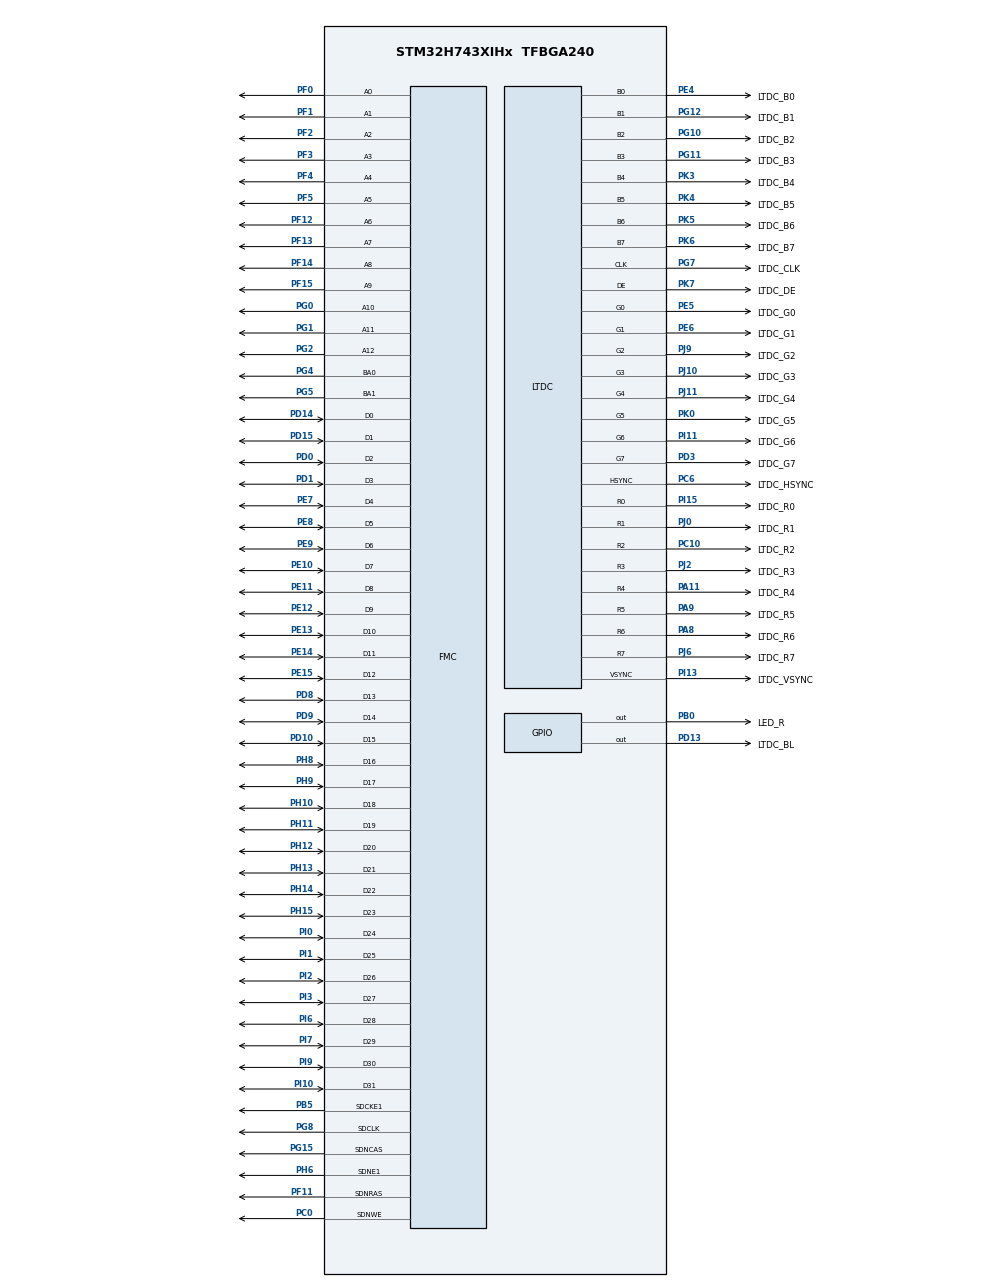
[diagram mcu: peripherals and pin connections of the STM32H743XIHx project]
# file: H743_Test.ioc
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CORTEX_M7.CPU_DCache=Enabled
CORTEX_M7.CPU_ICache=Enabled
DMA2D.Mode=DMA2D_R2M
FMC.BankMapConfig=FMC_SWAPBMAP_DISABLE
FMC.CASLatency1=FMC_SDRAM_CAS_LATENCY_3
FMC.ColumnBitsNumber1=FMC_SDRAM_COLUMN_BITS_NUM_9
FMC.ExitSelfRefreshDelay1=8
FMC.LoadToActiveDelay1=2
FMC.RCDDelay1=2
FMC.RPDelay1=2
FMC.ReadBurst1=FMC_SDRAM_RBURST_ENABLE
FMC.ReadPipeDelay1=FMC_SDRAM_RPIPE_DELAY_1
FMC.RowCycleDelay1=8
FMC.SDClockPeriod1=FMC_SDRAM_CLOCK_PERIOD_2
FMC.SelfRefreshTime1=5
FMC.WriteRecoveryTime1=4
LTDC.ActiveW=800
LTDC.Alpha0_L0=0
LTDC.Alpha_L0=255
LTDC.Alpha_L1=255
LTDC.BlendingFactor1_L0=LTDC_BLENDING_FACTOR1_PAxCA
LTDC.BlendingFactor1_L1=LTDC_BLENDING_FACTOR1_PAxCA
LTDC.BlendingFactor2_L0=LTDC_BLENDING_FACTOR2_PAxCA
LTDC.BlendingFactor2_L1=LTDC_BLENDING_FACTOR2_PAxCA
LTDC.FBStartAdress_L0=0xd2000000
LTDC.FBStartAdress_L1=0xD2000000+800*480*4
LTDC.HBP=46
LTDC.HFP=10
LTDC.HSync=1
LTDC.ImageHeight_L0=480
LTDC.ImageHeight_L1=480
LTDC.ImageWidth_L0=800
LTDC.ImageWidth_L1=800
LTDC.VBP=23
LTDC.VFP=22
LTDC.VSync=1
LTDC.WindowX1_L0=800
LTDC.WindowX1_L1=800
LTDC.WindowY1_L0=480
LTDC.WindowY1_L1=480
Mcu.Family=STM32H7
Mcu.Name=STM32H743XIHx
Mcu.Package=TFBGA240
NVIC.PriorityGroup=NVIC_PRIORITYGROUP_4
PA11.GPIO_Label=LTDC_R4
PA11.GPIO_PuPd=GPIO_PULLUP
PA11.GPIO_Speed=GPIO_SPEED_FREQ_VERY_HIGH
PA11.Mode=RGB888
PA11.Signal=LTDC_R4
PA8.GPIO_Label=LTDC_R6
PA8.GPIO_PuPd=GPIO_PULLUP
PA8.GPIO_Speed=GPIO_SPEED_FREQ_VERY_HIGH
PA8.Mode=RGB888
PA8.Signal=LTDC_R6
PA9.GPIO_Label=LTDC_R5
PA9.GPIO_PuPd=GPIO_PULLUP
PA9.GPIO_Speed=GPIO_SPEED_FREQ_VERY_HIGH
PA9.Mode=RGB888
PA9.Signal=LTDC_R5
PB0.GPIO_Label=LED_R
PB0.GPIO_PuPd=GPIO_PULLUP
PB0.GPIO_Speed=GPIO_SPEED_FREQ_HIGH
PB0.PinState=GPIO_PIN_SET
PB0.Signal=GPIO_Output
PB5.GPIO_Mode=GPIO_MODE_AF_PP
PB5.GPIO_PuPd=GPIO_PULLUP
PB5.GPIO_Speed_High_Default=GPIO_SPEED_FREQ_VERY_HIGH
PB5.Mode=SdramChipSelect2_1
PB5.Signal=FMC_SDCKE1
PC0.GPIO_Mode=GPIO_MODE_AF_PP
PC0.GPIO_PuPd=GPIO_PULLUP
PC0.GPIO_Speed_High_Default=GPIO_SPEED_FREQ_VERY_HIGH
PC0.Signal=FMC_SDNWE
PC10.GPIO_Label=LTDC_R2
PC10.GPIO_PuPd=GPIO_PULLUP
PC10.GPIO_Speed=GPIO_SPEED_FREQ_VERY_HIGH
PC10.Mode=RGB888
PC10.Signal=LTDC_R2
PC6.GPIO_Label=LTDC_HSYNC
PC6.GPIO_PuPd=GPIO_PULLUP
PC6.GPIO_Speed=GPIO_SPEED_FREQ_VERY_HIGH
PC6.Mode=RGB888
PC6.Signal=LTDC_HSYNC
PD0.GPIO_Mode=GPIO_MODE_AF_PP
PD0.GPIO_PuPd=GPIO_PULLUP
PD0.GPIO_Speed_High_Default=GPIO_SPEED_FREQ_VERY_HIGH
PD0.Signal=FMC_D2_DA2
PD1.GPIO_Mode=GPIO_MODE_AF_PP
PD1.GPIO_PuPd=GPIO_PULLUP
PD1.GPIO_Speed_High_Default=GPIO_SPEED_FREQ_VERY_HIGH
PD1.Signal=FMC_D3_DA3
PD10.GPIO_Mode=GPIO_MODE_AF_PP
PD10.GPIO_PuPd=GPIO_PULLUP
PD10.GPIO_Speed_High_Default=GPIO_SPEED_FREQ_VERY_HIGH
PD10.Signal=FMC_D15_DA15
PD13.GPIO_Label=LTDC_BL
PD13.GPIO_ModeDefaultOutputPP=GPIO_MODE_OUTPUT_PP
PD13.GPIO_PuPd=GPIO_PULLUP
PD13.GPIO_Speed=GPIO_SPEED_FREQ_HIGH
PD13.PinState=GPIO_PIN_SET
PD13.Signal=GPIO_Output
PD14.GPIO_Mode=GPIO_MODE_AF_PP
PD14.GPIO_PuPd=GPIO_PULLUP
PD14.GPIO_Speed_High_Default=GPIO_SPEED_FREQ_VERY_HIGH
PD14.Signal=FMC_D0_DA0
PD15.GPIO_Mode=GPIO_MODE_AF_PP
PD15.GPIO_PuPd=GPIO_PULLUP
PD15.GPIO_Speed_High_Default=GPIO_SPEED_FREQ_VERY_HIGH
PD15.Signal=FMC_D1_DA1
PD3.GPIO_Label=LTDC_G7
PD3.GPIO_PuPd=GPIO_PULLUP
PD3.GPIO_Speed=GPIO_SPEED_FREQ_VERY_HIGH
PD3.Mode=RGB888
PD3.Signal=LTDC_G7
PD8.GPIO_Mode=GPIO_MODE_AF_PP
PD8.GPIO_PuPd=GPIO_PULLUP
PD8.GPIO_Speed_High_Default=GPIO_SPEED_FREQ_VERY_HIGH
PD8.Signal=FMC_D13_DA13
PD9.GPIO_Mode=GPIO_MODE_AF_PP
PD9.GPIO_PuPd=GPIO_PULLUP
PD9.GPIO_Speed_High_Default=GPIO_SPEED_FREQ_VERY_HIGH
PD9.Signal=FMC_D14_DA14
PE10.GPIO_Mode=GPIO_MODE_AF_PP
PE10.GPIO_PuPd=GPIO_PULLUP
PE10.GPIO_Speed_High_Default=GPIO_SPEED_FREQ_VERY_HIGH
PE10.Signal=FMC_D7_DA7
PE11.GPIO_Mode=GPIO_MODE_AF_PP
PE11.GPIO_PuPd=GPIO_PULLUP
PE11.GPIO_Speed_High_Default=GPIO_SPEED_FREQ_VERY_HIGH
PE11.Signal=FMC_D8_DA8
PE12.GPIO_Mode=GPIO_MODE_AF_PP
PE12.GPIO_PuPd=GPIO_PULLUP
PE12.GPIO_Speed_High_Default=GPIO_SPEED_FREQ_VERY_HIGH
PE12.Signal=FMC_D9_DA9
PE13.GPIO_Mode=GPIO_MODE_AF_PP
PE13.GPIO_PuPd=GPIO_PULLUP
PE13.GPIO_Speed_High_Default=GPIO_SPEED_FREQ_VERY_HIGH
PE13.Signal=FMC_D10_DA10
PE14.GPIO_Mode=GPIO_MODE_AF_PP
PE14.GPIO_PuPd=GPIO_PULLUP
PE14.GPIO_Speed_High_Default=GPIO_SPEED_FREQ_VERY_HIGH
PE14.Signal=FMC_D11_DA11
PE15.GPIO_Mode=GPIO_MODE_AF_PP
PE15.GPIO_PuPd=GPIO_PULLUP
PE15.GPIO_Speed_High_Default=GPIO_SPEED_FREQ_VERY_HIGH
PE15.Signal=FMC_D12_DA12
PE4.GPIO_Label=LTDC_B0
PE4.GPIO_PuPd=GPIO_PULLUP
PE4.GPIO_Speed=GPIO_SPEED_FREQ_VERY_HIGH
PE4.Mode=RGB888
PE4.Signal=LTDC_B0
PE5.GPIO_Label=LTDC_G0
PE5.GPIO_PuPd=GPIO_PULLUP
PE5.GPIO_Speed=GPIO_SPEED_FREQ_VERY_HIGH
PE5.Mode=RGB888
PE5.Signal=LTDC_G0
PE6.GPIO_Label=LTDC_G1
PE6.GPIO_PuPd=GPIO_PULLUP
PE6.GPIO_Speed=GPIO_SPEED_FREQ_VERY_HIGH
PE6.Mode=RGB888
PE6.Signal=LTDC_G1
PE7.GPIO_Mode=GPIO_MODE_AF_PP
PE7.GPIO_PuPd=GPIO_PULLUP
PE7.GPIO_Speed_High_Default=GPIO_SPEED_FREQ_VERY_HIGH
PE7.Signal=FMC_D4_DA4
PE8.GPIO_Mode=GPIO_MODE_AF_PP
PE8.GPIO_PuPd=GPIO_PULLUP
PE8.GPIO_Speed_High_Default=GPIO_SPEED_FREQ_VERY_HIGH
PE8.Signal=FMC_D5_DA5
PE9.GPIO_Mode=GPIO_MODE_AF_PP
PE9.GPIO_PuPd=GPIO_PULLUP
PE9.GPIO_Speed_High_Default=GPIO_SPEED_FREQ_VERY_HIGH
PE9.Signal=FMC_D6_DA6
PF0.GPIO_Mode=GPIO_MODE_AF_PP
PF0.GPIO_PuPd=GPIO_PULLUP
PF0.GPIO_Speed_High_Default=GPIO_SPEED_FREQ_VERY_HIGH
PF0.Signal=FMC_A0
PF1.GPIO_Mode=GPIO_MODE_AF_PP
PF1.GPIO_PuPd=GPIO_PULLUP
PF1.GPIO_Speed_High_Default=GPIO_SPEED_FREQ_VERY_HIGH
PF1.Signal=FMC_A1
PF11.GPIO_Mode=GPIO_MODE_AF_PP
PF11.GPIO_PuPd=GPIO_PULLUP
PF11.GPIO_Speed_High_Default=GPIO_SPEED_FREQ_VERY_HIGH
PF11.Signal=FMC_SDNRAS
PF12.GPIO_Mode=GPIO_MODE_AF_PP
PF12.GPIO_PuPd=GPIO_PULLUP
PF12.GPIO_Speed_High_Default=GPIO_SPEED_FREQ_VERY_HIGH
PF12.Signal=FMC_A6
PF13.GPIO_Mode=GPIO_MODE_AF_PP
PF13.GPIO_PuPd=GPIO_PULLUP
PF13.GPIO_Speed_High_Default=GPIO_SPEED_FREQ_VERY_HIGH
PF13.Signal=FMC_A7
PF14.GPIO_Mode=GPIO_MODE_AF_PP
PF14.GPIO_PuPd=GPIO_PULLUP
PF14.GPIO_Speed_High_Default=GPIO_SPEED_FREQ_VERY_HIGH
PF14.Signal=FMC_A8
PF15.GPIO_Mode=GPIO_MODE_AF_PP
PF15.GPIO_PuPd=GPIO_PULLUP
PF15.GPIO_Speed_High_Default=GPIO_SPEED_FREQ_VERY_HIGH
PF15.Signal=FMC_A9
PF2.GPIO_Mode=GPIO_MODE_AF_PP
PF2.GPIO_PuPd=GPIO_PULLUP
PF2.GPIO_Speed_High_Default=GPIO_SPEED_FREQ_VERY_HIGH
PF2.Signal=FMC_A2
PF3.GPIO_Mode=GPIO_MODE_AF_PP
PF3.GPIO_PuPd=GPIO_PULLUP
PF3.GPIO_Speed_High_Default=GPIO_SPEED_FREQ_VERY_HIGH
PF3.Signal=FMC_A3
PF4.GPIO_Mode=GPIO_MODE_AF_PP
PF4.GPIO_PuPd=GPIO_PULLUP
PF4.GPIO_Speed_High_Default=GPIO_SPEED_FREQ_VERY_HIGH
PF4.Signal=FMC_A4
PF5.GPIO_Mode=GPIO_MODE_AF_PP
PF5.GPIO_PuPd=GPIO_PULLUP
PF5.GPIO_Speed_High_Default=GPIO_SPEED_FREQ_VERY_HIGH
PF5.Signal=FMC_A5
PG0.GPIO_Mode=GPIO_MODE_AF_PP
PG0.GPIO_PuPd=GPIO_PULLUP
PG0.GPIO_Speed_High_Default=GPIO_SPEED_FREQ_VERY_HIGH
PG0.Signal=FMC_A10
PG1.GPIO_PuPd=GPIO_PULLUP
PG1.Signal=FMC_A11
PG10.GPIO_Label=LTDC_B2
PG10.GPIO_PuPd=GPIO_PULLUP
PG10.GPIO_Speed=GPIO_SPEED_FREQ_VERY_HIGH
PG10.Mode=RGB888
PG10.Signal=LTDC_B2
PG11.GPIO_Label=LTDC_B3
PG11.GPIO_PuPd=GPIO_PULLUP
PG11.GPIO_Speed=GPIO_SPEED_FREQ_VERY_HIGH
PG11.Mode=RGB888
PG11.Signal=LTDC_B3
PG12.GPIO_Label=LTDC_B1
PG12.GPIO_PuPd=GPIO_PULLUP
PG12.GPIO_Speed=GPIO_SPEED_FREQ_VERY_HIGH
PG12.Mode=RGB888
PG12.Signal=LTDC_B1
PG15.GPIO_Mode=GPIO_MODE_AF_PP
PG15.GPIO_PuPd=GPIO_PULLUP
PG15.GPIO_Speed_High_Default=GPIO_SPEED_FREQ_VERY_HIGH
PG15.Signal=FMC_SDNCAS
PG2.GPIO_PuPd=GPIO_PULLUP
PG2.Signal=FMC_A12
PG4.GPIO_Mode=GPIO_MODE_AF_PP
PG4.GPIO_PuPd=GPIO_PULLUP
PG4.GPIO_Speed_High_Default=GPIO_SPEED_FREQ_VERY_HIGH
PG4.Signal=FMC_A14_BA0
PG5.GPIO_Mode=GPIO_MODE_AF_PP
PG5.GPIO_PuPd=GPIO_PULLUP
PG5.GPIO_Speed_High_Default=GPIO_SPEED_FREQ_VERY_HIGH
PG5.Signal=FMC_A15_BA1
PG7.GPIO_Label=LTDC_CLK
PG7.GPIO_PuPd=GPIO_PULLUP
PG7.GPIO_Speed=GPIO_SPEED_FREQ_VERY_HIGH
PG7.Mode=RGB888
PG7.Signal=LTDC_CLK
PG8.GPIO_Mode=GPIO_MODE_AF_PP
PG8.GPIO_PuPd=GPIO_PULLUP
PG8.GPIO_Speed_High_Default=GPIO_SPEED_FREQ_VERY_HIGH
PG8.Signal=FMC_SDCLK
PH0-OSC_IN\ (PH0).Mode=HSE-External-Oscillator
PH0-OSC_IN\ (PH0).Signal=RCC_OSC_IN
PH1-OSC_OUT\ (PH1).Mode=HSE-External-Oscillator
PH1-OSC_OUT\ (PH1).Signal=RCC_OSC_OUT
PH10.GPIO_PuPd=GPIO_PULLUP
PH10.Signal=FMC_D18
PH11.GPIO_PuPd=GPIO_PULLUP
PH11.Signal=FMC_D19
PH12.GPIO_PuPd=GPIO_PULLUP
PH12.Signal=FMC_D20
PH13.GPIO_PuPd=GPIO_PULLUP
PH13.Signal=FMC_D21
PH14.GPIO_PuPd=GPIO_PULLUP
PH14.Signal=FMC_D22
PH15.GPIO_PuPd=GPIO_PULLUP
PH15.Signal=FMC_D23
PH6.GPIO_Mode=GPIO_MODE_AF_PP
PH6.GPIO_PuPd=GPIO_PULLUP
PH6.GPIO_Speed_High_Default=GPIO_SPEED_FREQ_VERY_HIGH
PH6.Mode=SdramChipSelect2_1
PH6.Signal=FMC_SDNE1
PH8.GPIO_PuPd=GPIO_PULLUP
PH8.Signal=FMC_D16
PH9.GPIO_PuPd=GPIO_PULLUP
PH9.Signal=FMC_D17
PI0.GPIO_PuPd=GPIO_PULLUP
PI0.Signal=FMC_D24
PI1.GPIO_PuPd=GPIO_PULLUP
PI1.Signal=FMC_D25
PI10.GPIO_PuPd=GPIO_PULLUP
PI10.Signal=FMC_D31
PI11.GPIO_Label=LTDC_G6
PI11.GPIO_PuPd=GPIO_PULLUP
PI11.GPIO_Speed=GPIO_SPEED_FREQ_VERY_HIGH
PI11.Mode=RGB888
PI11.Signal=LTDC_G6
PI13.GPIO_Label=LTDC_VSYNC
PI13.GPIO_PuPd=GPIO_PULLUP
PI13.GPIO_Speed=GPIO_SPEED_FREQ_VERY_HIGH
PI13.Mode=RGB888
PI13.Signal=LTDC_VSYNC
PI15.GPIO_Label=LTDC_R0
PI15.GPIO_PuPd=GPIO_PULLUP
PI15.GPIO_Speed=GPIO_SPEED_FREQ_VERY_HIGH
PI15.Mode=RGB888
PI15.Signal=LTDC_R0
PI2.GPIO_PuPd=GPIO_PULLUP
PI2.Signal=FMC_D26
PI3.GPIO_PuPd=GPIO_PULLUP
PI3.Signal=FMC_D27
PI6.GPIO_PuPd=GPIO_PULLUP
PI6.Signal=FMC_D28
PI7.GPIO_PuPd=GPIO_PULLUP
PI7.Signal=FMC_D29
PI9.GPIO_PuPd=GPIO_PULLUP
PI9.Signal=FMC_D30
PJ0.GPIO_Label=LTDC_R1
PJ0.GPIO_PuPd=GPIO_PULLUP
PJ0.GPIO_Speed=GPIO_SPEED_FREQ_VERY_HIGH
PJ0.Mode=RGB888
PJ0.Signal=LTDC_R1
PJ10.GPIO_Label=LTDC_G3
PJ10.GPIO_PuPd=GPIO_PULLUP
PJ10.GPIO_Speed=GPIO_SPEED_FREQ_VERY_HIGH
PJ10.Mode=RGB888
PJ10.Signal=LTDC_G3
PJ11.GPIO_Label=LTDC_G4
PJ11.GPIO_PuPd=GPIO_PULLUP
PJ11.GPIO_Speed=GPIO_SPEED_FREQ_VERY_HIGH
PJ11.Mode=RGB888
PJ11.Signal=LTDC_G4
PJ2.GPIO_Label=LTDC_R3
PJ2.GPIO_PuPd=GPIO_PULLUP
PJ2.GPIO_Speed=GPIO_SPEED_FREQ_VERY_HIGH
PJ2.Mode=RGB888
PJ2.Signal=LTDC_R3
PJ6.GPIO_Label=LTDC_R7
PJ6.GPIO_PuPd=GPIO_PULLUP
PJ6.GPIO_Speed=GPIO_SPEED_FREQ_VERY_HIGH
PJ6.Mode=RGB888
PJ6.Signal=LTDC_R7
PJ9.GPIO_Label=LTDC_G2
PJ9.GPIO_PuPd=GPIO_PULLUP
PJ9.GPIO_Speed=GPIO_SPEED_FREQ_VERY_HIGH
PJ9.Mode=RGB888
PJ9.Signal=LTDC_G2
PK0.GPIO_Label=LTDC_G5
PK0.GPIO_PuPd=GPIO_PULLUP
PK0.GPIO_Speed=GPIO_SPEED_FREQ_VERY_HIGH
PK0.Mode=RGB888
PK0.Signal=LTDC_G5
PK3.GPIO_Label=LTDC_B4
PK3.GPIO_PuPd=GPIO_PULLUP
PK3.GPIO_Speed=GPIO_SPEED_FREQ_VERY_HIGH
PK3.Mode=RGB888
PK3.Signal=LTDC_B4
PK4.GPIO_Label=LTDC_B5
PK4.GPIO_PuPd=GPIO_PULLUP
PK4.GPIO_Speed=GPIO_SPEED_FREQ_VERY_HIGH
PK4.Mode=RGB888
PK4.Signal=LTDC_B5
PK5.GPIO_Label=LTDC_B6
PK5.GPIO_PuPd=GPIO_PULLUP
PK5.GPIO_Speed=GPIO_SPEED_FREQ_VERY_HIGH
PK5.Mode=RGB888
PK5.Signal=LTDC_B6
PK6.GPIO_Label=LTDC_B7
PK6.GPIO_PuPd=GPIO_PULLUP
PK6.GPIO_Speed=GPIO_SPEED_FREQ_VERY_HIGH
PK6.Mode=RGB888
PK6.Signal=LTDC_B7
PK7.GPIO_Label=LTDC_DE
PK7.GPIO_PuPd=GPIO_PULLUP
PK7.GPIO_Speed=GPIO_SPEED_FREQ_VERY_HIGH
PK7.Mode=RGB888
PK7.Signal=LTDC_DE
ProjectManager.HeapSize=0x200
ProjectManager.StackSize=0x400
ProjectManager.TargetToolchain=Makefile
RCC.ADCFreq_Value=360000000
RCC.APB1Freq_Value=120000000
RCC.APB2Freq_Value=120000000
RCC.APB3Freq_Value=120000000
RCC.APB4Freq_Value=120000000
RCC.CortexFreq_Value=480000000
RCC.D1PPRE=RCC_APB3_DIV2
RCC.D2PPRE1=RCC_APB1_DIV2
RCC.D2PPRE2=RCC_APB2_DIV2
RCC.D3PPRE=RCC_APB4_DIV2
RCC.DIVM1=5
RCC.DIVM2=5
RCC.DIVM3=25
RCC.DIVN1=192
RCC.DIVN2=144
RCC.DIVN3=270
RCC.DIVR2=3
RCC.DIVR3=10
RCC.FMCCLockSelection=RCC_FMCCLKSOURCE_PLL2
RCC.HCLKFreq_Value=240000000
RCC.HPRE=RCC_HCLK_DIV2
RCC.PLL2FRACN=0
RCC.PLL3FRACN=0
RCC.PLLFRACN=0
RCC.PLLSourceVirtual=RCC_PLLSOURCE_HSE
RCC.SYSCLKFreq_VALUE=480000000
RCC.SYSCLKSource=RCC_SYSCLKSOURCE_PLLCLK
RCC.USBFreq_Value=480000000
SH.FMC_A0.0=FMC_A0,13b-sda1
SH.FMC_A1.0=FMC_A1,13b-sda1
SH.FMC_A10.0=FMC_A10,13b-sda1
SH.FMC_A11.0=FMC_A11,13b-sda1
SH.FMC_A12.0=FMC_A12,13b-sda1
SH.FMC_A14_BA0.0=FMC_BA0,FourSdramBanks1
SH.FMC_A15_BA1.0=FMC_BA1,FourSdramBanks1
SH.FMC_A2.0=FMC_A2,13b-sda1
SH.FMC_A3.0=FMC_A3,13b-sda1
SH.FMC_A4.0=FMC_A4,13b-sda1
SH.FMC_A5.0=FMC_A5,13b-sda1
SH.FMC_A6.0=FMC_A6,13b-sda1
SH.FMC_A7.0=FMC_A7,13b-sda1
SH.FMC_A8.0=FMC_A8,13b-sda1
SH.FMC_A9.0=FMC_A9,13b-sda1
SH.FMC_D0_DA0.0=FMC_D0,sd-32b-d1
SH.FMC_D10_DA10.0=FMC_D10,sd-32b-d1
SH.FMC_D11_DA11.0=FMC_D11,sd-32b-d1
SH.FMC_D12_DA12.0=FMC_D12,sd-32b-d1
SH.FMC_D13_DA13.0=FMC_D13,sd-32b-d1
SH.FMC_D14_DA14.0=FMC_D14,sd-32b-d1
SH.FMC_D15_DA15.0=FMC_D15,sd-32b-d1
SH.FMC_D16.0=FMC_D16,sd-32b-d1
SH.FMC_D17.0=FMC_D17,sd-32b-d1
SH.FMC_D18.0=FMC_D18,sd-32b-d1
SH.FMC_D19.0=FMC_D19,sd-32b-d1
SH.FMC_D1_DA1.0=FMC_D1,sd-32b-d1
SH.FMC_D20.0=FMC_D20,sd-32b-d1
SH.FMC_D21.0=FMC_D21,sd-32b-d1
SH.FMC_D22.0=FMC_D22,sd-32b-d1
SH.FMC_D23.0=FMC_D23,sd-32b-d1
SH.FMC_D24.0=FMC_D24,sd-32b-d1
SH.FMC_D25.0=FMC_D25,sd-32b-d1
SH.FMC_D26.0=FMC_D26,sd-32b-d1
SH.FMC_D27.0=FMC_D27,sd-32b-d1
SH.FMC_D28.0=FMC_D28,sd-32b-d1
SH.FMC_D29.0=FMC_D29,sd-32b-d1
SH.FMC_D2_DA2.0=FMC_D2,sd-32b-d1
SH.FMC_D30.0=FMC_D30,sd-32b-d1
SH.FMC_D31.0=FMC_D31,sd-32b-d1
SH.FMC_D3_DA3.0=FMC_D3,sd-32b-d1
SH.FMC_D4_DA4.0=FMC_D4,sd-32b-d1
SH.FMC_D5_DA5.0=FMC_D5,sd-32b-d1
SH.FMC_D6_DA6.0=FMC_D6,sd-32b-d1
SH.FMC_D7_DA7.0=FMC_D7,sd-32b-d1
SH.FMC_D8_DA8.0=FMC_D8,sd-32b-d1
SH.FMC_D9_DA9.0=FMC_D9,sd-32b-d1
SH.FMC_SDCLK.0=FMC_SDCLK,13b-sda1
SH.FMC_SDNCAS.0=FMC_SDNCAS,13b-sda1
SH.FMC_SDNRAS.0=FMC_SDNRAS,13b-sda1
SH.FMC_SDNWE.0=FMC_SDNWE,13b-sda1
VP_DMA2D_VS_DMA2D.Mode=DMA2D_Activate
board=custom

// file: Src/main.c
/* USER CODE BEGIN Header */
/**
 ******************************************************************************
 * @file           : main.c
 * @brief          : Main program body
 ******************************************************************************
 * @attention
 *
 * <h2><center>&copy; Copyright (c) 2020 STMicroelectronics.
 * All rights reserved.</center></h2>
 *
 * This software component is licensed by ST under BSD 3-Clause license,
 * the "License"; You may not use this file except in compliance with the
 * License. You may obtain a copy of the License at:
 *                        opensource.org/licenses/BSD-3-Clause
 *
 ******************************************************************************
 */
/* USER CODE END Header */

#include "main.h"

DMA2D_HandleTypeDef hdma2d;

LTDC_HandleTypeDef hltdc;

SDRAM_HandleTypeDef hsdram1;

/* USER CODE BEGIN PV */
typedef struct
{
  uint32_t TextColor;
  uint32_t BackColor;
  sFONT *pFont;
} LCD_DrawPropTypeDef;

typedef struct
{
  int16_t X;
  int16_t Y;
} Point, *pPoint;

typedef enum
{
  CENTER_MODE = 0X01,
  RIGHT_MODE = 0X02,
  LEFT_MODE = 0X03
} Text_AlignModeTypedef;

static LCD_DrawPropTypeDef DrawProp[2];
/* USER CODE END PV */

void SystemClock_Config(void);
static void MX_GPIO_Init(void);
static void MX_DMA2D_Init(void);
static void MX_FMC_Init(void);
static void MX_LTDC_Init(void);
/* USER CODE BEGIN PFP */
void LCD_SetLayerAddress(uint16_t LayerIndex, uint32_t Address);
void LCD_SetTextColor(uint16_t LayerIndex, uint32_t Color);
void LCD_SetBackColor(uint16_t LayerIndex, uint32_t Color);
void LCD_SetColors(uint16_t LayerIndex, uint32_t TextColor, uint32_t BackColor);
void LCD_SetFont(uint16_t LayerIndex, sFONT *fonts);
void LCD_DrawPixel(uint16_t LayerIndex, uint16_t Xpos, uint16_t Ypos, uint32_t RGB_Code);
void LCD_DisplayChar(uint16_t LayerIndex, uint16_t Xpos, uint16_t Ypos, uint8_t Ascii);
static void LL_FillBuffer(uint32_t LayerIndex, void *pDst, uint32_t xSize, uint32_t ySize, uint32_t OffLine,
                          uint32_t ColorIndex);
static void DrawChar(uint16_t LayerIndex, uint16_t Xpos, uint16_t Ypos, const uint8_t *c);
void LCD_DisplayOn(void);
void LCD_DisplayOff(void);
void LCD_Clear(uint16_t LayerIndex, uint32_t Color);
uint32_t LCD_GetXSize(uint16_t LayerIndex);
uint32_t LCD_GetYSize(uint16_t LayerIndex);
/* USER CODE END PFP */

int main(void)
{

  /* Enable I-Cache---------------------------------------------------------*/
  SCB_EnableICache();

  /* Enable D-Cache---------------------------------------------------------*/
  SCB_EnableDCache();

  /* MCU Configuration--------------------------------------------------------*/

  /* Reset of all peripherals, Initializes the Flash interface and the Systick. */
  HAL_Init();

  /* USER CODE BEGIN Init */
  HAL_MspInit();
  /* USER CODE END Init */

  /* Configure the system clock */
  SystemClock_Config();

  /* USER CODE BEGIN SysInit */
  Board_MPU_Config(0, MPU_Normal_WT, 0xD0000000, MPU_32MB);
  Board_MPU_Config(1, MPU_Normal_WT, 0x24000000, MPU_512KB);
  /* USER CODE END SysInit */

  /* Initialize all configured peripherals */
  MX_GPIO_Init();
  MX_DMA2D_Init();
  MX_FMC_Init();
  MX_LTDC_Init();
  /* USER CODE BEGIN 2 */
  LCD_Clear(0, LCD_COLOR_BLACK);
  /* USER CODE END 2 */

  /* Infinite loop */
  while (1)
  {

    /* USER CODE BEGIN 3 */
    HAL_GPIO_TogglePin(LED_R_GPIO_Port, LED_R_Pin);
    HAL_Delay(500);
    HAL_GPIO_TogglePin(LED_R_GPIO_Port, LED_R_Pin);
    HAL_Delay(500);
    LCD_SetColors(0, LCD_COLOR_BLACK, LCD_COLOR_WHITE);
    LCD_SetFont(0, &Font24);
    LCD_DisplayChar(0, 30, 30, 0x24);
  }
  /* USER CODE END 3 */
}

void SystemClock_Config(void)
{
  RCC_OscInitTypeDef RCC_OscInitStruct = {0};
  RCC_ClkInitTypeDef RCC_ClkInitStruct = {0};
  RCC_PeriphCLKInitTypeDef PeriphClkInitStruct = {0};

  /** Supply configuration update enable
   */
  HAL_PWREx_ConfigSupply(PWR_LDO_SUPPLY);
  /** Configure the main internal regulator output voltage
   */
  __HAL_PWR_VOLTAGESCALING_CONFIG(PWR_REGULATOR_VOLTAGE_SCALE0);

  while (!__HAL_PWR_GET_FLAG(PWR_FLAG_VOSRDY))
  {
  }
  /** Macro to configure the PLL clock source
   */
  __HAL_RCC_PLL_PLLSOURCE_CONFIG(RCC_PLLSOURCE_HSE);
  /** Initializes the CPU, AHB and APB busses clocks
   */
  RCC_OscInitStruct.OscillatorType = RCC_OSCILLATORTYPE_HSE;
  RCC_OscInitStruct.HSEState = RCC_HSE_ON;
  RCC_OscInitStruct.PLL.PLLState = RCC_PLL_ON;
  RCC_OscInitStruct.PLL.PLLSource = RCC_PLLSOURCE_HSE;
  RCC_OscInitStruct.PLL.PLLM = 5;
  RCC_OscInitStruct.PLL.PLLN = 192;
  RCC_OscInitStruct.PLL.PLLP = 2;
  RCC_OscInitStruct.PLL.PLLQ = 2;
  RCC_OscInitStruct.PLL.PLLR = 2;
  RCC_OscInitStruct.PLL.PLLRGE = RCC_PLL1VCIRANGE_2;
  RCC_OscInitStruct.PLL.PLLVCOSEL = RCC_PLL1VCOWIDE;
  RCC_OscInitStruct.PLL.PLLFRACN = 0;
  if (HAL_RCC_OscConfig(&RCC_OscInitStruct) != HAL_OK)
  {
    Error_Handler();
  }
  /** Initializes the CPU, AHB and APB busses clocks
   */
  RCC_ClkInitStruct.ClockType = RCC_CLOCKTYPE_HCLK | RCC_CLOCKTYPE_SYSCLK | RCC_CLOCKTYPE_PCLK1 | RCC_CLOCKTYPE_PCLK2 |
                                RCC_CLOCKTYPE_D3PCLK1 | RCC_CLOCKTYPE_D1PCLK1;
  RCC_ClkInitStruct.SYSCLKSource = RCC_SYSCLKSOURCE_PLLCLK;
  RCC_ClkInitStruct.SYSCLKDivider = RCC_SYSCLK_DIV1;
  RCC_ClkInitStruct.AHBCLKDivider = RCC_HCLK_DIV2;
  RCC_ClkInitStruct.APB3CLKDivider = RCC_APB3_DIV2;
  RCC_ClkInitStruct.APB1CLKDivider = RCC_APB1_DIV2;
  RCC_ClkInitStruct.APB2CLKDivider = RCC_APB2_DIV2;
  RCC_ClkInitStruct.APB4CLKDivider = RCC_APB4_DIV2;

  if (HAL_RCC_ClockConfig(&RCC_ClkInitStruct, FLASH_LATENCY_4) != HAL_OK)
  {
    Error_Handler();
  }
  PeriphClkInitStruct.PeriphClockSelection = RCC_PERIPHCLK_LTDC | RCC_PERIPHCLK_FMC;
  PeriphClkInitStruct.PLL2.PLL2M = 5;
  PeriphClkInitStruct.PLL2.PLL2N = 144;
  PeriphClkInitStruct.PLL2.PLL2P = 2;
  PeriphClkInitStruct.PLL2.PLL2Q = 2;
  PeriphClkInitStruct.PLL2.PLL2R = 3;
  PeriphClkInitStruct.PLL2.PLL2RGE = RCC_PLL2VCIRANGE_2;
  PeriphClkInitStruct.PLL2.PLL2VCOSEL = RCC_PLL2VCOWIDE;
  PeriphClkInitStruct.PLL2.PLL2FRACN = 0;
  PeriphClkInitStruct.PLL3.PLL3M = 25;
  PeriphClkInitStruct.PLL3.PLL3N = 270;
  PeriphClkInitStruct.PLL3.PLL3P = 2;
  PeriphClkInitStruct.PLL3.PLL3Q = 2;
  PeriphClkInitStruct.PLL3.PLL3R = 10;
  PeriphClkInitStruct.PLL3.PLL3RGE = RCC_PLL3VCIRANGE_0;
  PeriphClkInitStruct.PLL3.PLL3VCOSEL = RCC_PLL3VCOWIDE;
  PeriphClkInitStruct.PLL3.PLL3FRACN = 0;
  PeriphClkInitStruct.FmcClockSelection = RCC_FMCCLKSOURCE_PLL2;
  if (HAL_RCCEx_PeriphCLKConfig(&PeriphClkInitStruct) != HAL_OK)
  {
    Error_Handler();
  }
}

static void MX_DMA2D_Init(void)
{

  hdma2d.Instance = DMA2D;
  hdma2d.Init.Mode = DMA2D_R2M;
  hdma2d.Init.ColorMode = DMA2D_OUTPUT_ARGB8888;
  hdma2d.Init.OutputOffset = 0;
  hdma2d.Init.BytesSwap = DMA2D_BYTES_REGULAR;
  hdma2d.Init.LineOffsetMode = DMA2D_LOM_PIXELS;
  hdma2d.LayerCfg[1].AlphaInverted = DMA2D_REGULAR_ALPHA;
  if (HAL_DMA2D_Init(&hdma2d) != HAL_OK)
  {
    Error_Handler();
  }
  /* USER CODE BEGIN DMA2D_Init 2 */
  HAL_DMA2D_MspInit(&hdma2d);
  /* USER CODE END DMA2D_Init 2 */
}

static void MX_LTDC_Init(void)
{

  LTDC_LayerCfgTypeDef pLayerCfg = {0};
  LTDC_LayerCfgTypeDef pLayerCfg1 = {0};

  hltdc.Instance = LTDC;
  hltdc.Init.HSPolarity = LTDC_HSPOLARITY_AL;
  hltdc.Init.VSPolarity = LTDC_VSPOLARITY_AL;
  hltdc.Init.DEPolarity = LTDC_DEPOLARITY_AL;
  hltdc.Init.PCPolarity = LTDC_PCPOLARITY_IPC;
  hltdc.Init.HorizontalSync = 0;
  hltdc.Init.VerticalSync = 0;
  hltdc.Init.AccumulatedHBP = 46;
  hltdc.Init.AccumulatedVBP = 23;
  hltdc.Init.AccumulatedActiveW = 846;
  hltdc.Init.AccumulatedActiveH = 503;
  hltdc.Init.TotalWidth = 856;
  hltdc.Init.TotalHeigh = 525;
  hltdc.Init.Backcolor.Blue = 0;
  hltdc.Init.Backcolor.Green = 0;
  hltdc.Init.Backcolor.Red = 0;
  if (HAL_LTDC_Init(&hltdc) != HAL_OK)
  {
    Error_Handler();
  }
  pLayerCfg.WindowX0 = 0;
  pLayerCfg.WindowX1 = 800;
  pLayerCfg.WindowY0 = 0;
  pLayerCfg.WindowY1 = 480;
  pLayerCfg.PixelFormat = LTDC_PIXEL_FORMAT_ARGB8888;
  pLayerCfg.Alpha = 255;
  pLayerCfg.Alpha0 = 0;
  pLayerCfg.BlendingFactor1 = LTDC_BLENDING_FACTOR1_PAxCA;
  pLayerCfg.BlendingFactor2 = LTDC_BLENDING_FACTOR2_PAxCA;
  pLayerCfg.FBStartAdress = 0xd2000000;
  pLayerCfg.ImageWidth = 800;
  pLayerCfg.ImageHeight = 480;
  pLayerCfg.Backcolor.Blue = 0;
  pLayerCfg.Backcolor.Green = 0;
  pLayerCfg.Backcolor.Red = 0;
  if (HAL_LTDC_ConfigLayer(&hltdc, &pLayerCfg, 0) != HAL_OK)
  {
    Error_Handler();
  }
  pLayerCfg1.WindowX0 = 0;
  pLayerCfg1.WindowX1 = 800;
  pLayerCfg1.WindowY0 = 0;
  pLayerCfg1.WindowY1 = 480;
  pLayerCfg1.PixelFormat = LTDC_PIXEL_FORMAT_ARGB8888;
  pLayerCfg1.Alpha = 255;
  pLayerCfg1.Alpha0 = 0;
  pLayerCfg1.BlendingFactor1 = LTDC_BLENDING_FACTOR1_PAxCA;
  pLayerCfg1.BlendingFactor2 = LTDC_BLENDING_FACTOR2_PAxCA;
  pLayerCfg1.FBStartAdress = 0xD2000000 + 800 * 480 * 4;
  pLayerCfg1.ImageWidth = 800;
  pLayerCfg1.ImageHeight = 480;
  pLayerCfg1.Backcolor.Blue = 0;
  pLayerCfg1.Backcolor.Green = 0;
  pLayerCfg1.Backcolor.Red = 0;
  if (HAL_LTDC_ConfigLayer(&hltdc, &pLayerCfg1, 1) != HAL_OK)
  {
    Error_Handler();
  }
  /* USER CODE BEGIN LTDC_Init 2 */
  DrawProp[1].BackColor = LCD_COLOR_WHITE;
  DrawProp[1].pFont = &LCD_DEFAULT_FONT;
  DrawProp[1].TextColor = LCD_COLOR_BLACK;
  __HAL_LTDC_RELOAD_CONFIG(&hltdc);

  DrawProp[0].BackColor = LCD_COLOR_WHITE;
  DrawProp[0].pFont = &LCD_DEFAULT_FONT;
  DrawProp[0].TextColor = LCD_COLOR_BLACK;
  __HAL_LTDC_RELOAD_CONFIG(&hltdc);

  HAL_LTDC_MspInit(&hltdc);
  /* USER CODE END LTDC_Init 2 */
}

/* FMC initialization function */
static void MX_FMC_Init(void)
{

  FMC_SDRAM_TimingTypeDef SdramTiming = {0};

  /** Perform the SDRAM1 memory initialization sequence
   */
  hsdram1.Instance = FMC_SDRAM_DEVICE;
  /* hsdram1.Init */
  hsdram1.Init.SDBank = FMC_SDRAM_BANK2;
  hsdram1.Init.ColumnBitsNumber = FMC_SDRAM_COLUMN_BITS_NUM_9;
  hsdram1.Init.RowBitsNumber = FMC_SDRAM_ROW_BITS_NUM_13;
  hsdram1.Init.MemoryDataWidth = FMC_SDRAM_MEM_BUS_WIDTH_32;
  hsdram1.Init.InternalBankNumber = FMC_SDRAM_INTERN_BANKS_NUM_4;
  hsdram1.Init.CASLatency = FMC_SDRAM_CAS_LATENCY_3;
  hsdram1.Init.WriteProtection = FMC_SDRAM_WRITE_PROTECTION_DISABLE;
  hsdram1.Init.SDClockPeriod = FMC_SDRAM_CLOCK_PERIOD_2;
  hsdram1.Init.ReadBurst = FMC_SDRAM_RBURST_ENABLE;
  hsdram1.Init.ReadPipeDelay = FMC_SDRAM_RPIPE_DELAY_1;
  /* SdramTiming */
  SdramTiming.LoadToActiveDelay = 2;
  SdramTiming.ExitSelfRefreshDelay = 8;
  SdramTiming.SelfRefreshTime = 5;
  SdramTiming.RowCycleDelay = 8;
  SdramTiming.WriteRecoveryTime = 4;
  SdramTiming.RPDelay = 2;
  SdramTiming.RCDDelay = 2;

  if (HAL_SDRAM_Init(&hsdram1, &SdramTiming) != HAL_OK)
  {
    Error_Handler();
  }

  /* USER CODE BEGIN FMC_Init 2 */
  HAL_SDRAM_MspInit(&hsdram1);
  /* USER CODE END FMC_Init 2 */
}

static void MX_GPIO_Init(void)
{
  GPIO_InitTypeDef GPIO_InitStruct = {0};

  /* GPIO Ports Clock Enable */
  __HAL_RCC_GPIOI_CLK_ENABLE();
  __HAL_RCC_GPIOB_CLK_ENABLE();
  __HAL_RCC_GPIOK_CLK_ENABLE();
  __HAL_RCC_GPIOG_CLK_ENABLE();
  __HAL_RCC_GPIOC_CLK_ENABLE();
  __HAL_RCC_GPIOD_CLK_ENABLE();
  __HAL_RCC_GPIOH_CLK_ENABLE();
  __HAL_RCC_GPIOE_CLK_ENABLE();
  __HAL_RCC_GPIOA_CLK_ENABLE();
  __HAL_RCC_GPIOF_CLK_ENABLE();
  __HAL_RCC_GPIOJ_CLK_ENABLE();

  /*Configure GPIO pin Output Level */
  HAL_GPIO_WritePin(LTDC_BL_GPIO_Port, LTDC_BL_Pin, GPIO_PIN_SET);

  /*Configure GPIO pin Output Level */
  HAL_GPIO_WritePin(LED_R_GPIO_Port, LED_R_Pin, GPIO_PIN_SET);

  /*Configure GPIO pin : LTDC_BL_Pin */
  GPIO_InitStruct.Pin = LTDC_BL_Pin;
  GPIO_InitStruct.Mode = GPIO_MODE_OUTPUT_PP;
  GPIO_InitStruct.Pull = GPIO_PULLUP;
  GPIO_InitStruct.Speed = GPIO_SPEED_FREQ_HIGH;
  HAL_GPIO_Init(LTDC_BL_GPIO_Port, &GPIO_InitStruct);

  /*Configure GPIO pin : LED_R_Pin */
  GPIO_InitStruct.Pin = LED_R_Pin;
  GPIO_InitStruct.Mode = GPIO_MODE_OUTPUT_PP;
  GPIO_InitStruct.Pull = GPIO_PULLUP;
  GPIO_InitStruct.Speed = GPIO_SPEED_FREQ_HIGH;
  HAL_GPIO_Init(LED_R_GPIO_Port, &GPIO_InitStruct);
}

/* USER CODE BEGIN 4 */
void LCD_SetLayerAddress(uint16_t LayerIndex, uint32_t Address) { HAL_LTDC_SetAddress(&hltdc, Address, LayerIndex); }

void LCD_SetTextColor(uint16_t LayerIndex, uint32_t Color) { DrawProp[LayerIndex].TextColor = Color; }

void LCD_SetBackColor(uint16_t LayerIndex, uint32_t Color) { DrawProp[LayerIndex].BackColor = Color; }

void LCD_SetFont(uint16_t LayerIndex, sFONT *fonts) { DrawProp[LayerIndex].pFont = fonts; }

void LCD_SetColors(uint16_t LayerIndex, uint32_t TextColor, uint32_t BackColor)
{
  LCD_SetTextColor(LayerIndex, TextColor);
  LCD_SetBackColor(LayerIndex, BackColor);
}

/**
 * @brief  ???LCD?????��??X????��
 * @param  LayrerIndex??????????
 * @retval X????��
 */
uint32_t LCD_GetXSize(uint16_t LayerIndex) { return hltdc.LayerCfg[LayerIndex].ImageWidth; }

/**
 * @brief  ???LCD?????��??Y????��
 * @retval Y????��
 */
uint32_t LCD_GetYSize(uint16_t LayerIndex) { return hltdc.LayerCfg[LayerIndex].ImageHeight; }

/**
 * @brief  ?????????
 * @param  LayrerIndex??????????
 * @param  Xpos: X?????????
 * @param  Ypos: Y?????????
 * @param  Ascii: ??? ascii ??,??��?? 0x20 ??0x7E ??
 * @retval ??
 */
void LCD_DisplayChar(uint16_t LayerIndex, uint16_t Xpos, uint16_t Ypos, uint8_t Ascii)
{
  DrawChar(LayerIndex, Xpos, Ypos,
           &DrawProp[LayerIndex].pFont->table[(Ascii - ' ') * DrawProp[LayerIndex].pFont->Height *
                                              ((DrawProp[LayerIndex].pFont->Width + 7) / 8)]);
}

/**
 * @brief ?????????
 * @param LayerIndex???????????
 * @param Xpos????????????��??
 * @param Ypos????????????��??
 * @param c?????????????????
 * @retval ??
 */
static void DrawChar(uint16_t LayerIndex, uint16_t Xpos, uint16_t Ypos, const uint8_t *c)
{
  uint32_t i = 0, j = 0;
  uint16_t height, width;
  uint8_t offset;
  uint8_t *pchar;
  uint32_t line;

  height = DrawProp[LayerIndex].pFont->Height; //????????????????
  width = DrawProp[LayerIndex].pFont->Width;   //????????????????

  offset = 8 * ((width + 7) / 8) - width; //???????????????????????????��??��-??????

  for (i = 0; i < height; i++) //????????????
  {
    pchar = ((uint8_t *)c + (width + 7) / 8 * i); //???????????????????????

    switch (((width + 7) / 8))
    {
    case 1:
      line = pchar[0]; //?????????��??8????????????
      break;

    case 2:
      line = (pchar[0] << 8) | pchar[1]; //????????????8��??16????????????
      break;

    case 3:
    default:
      line = (pchar[0] << 16) | (pchar[1] << 8) | pchar[2]; //????????????16��??24????????????
      break;
    }

    for (j = 0; j < width; j++) //????????????
    {
      if (line & (1 << (width - j + offset - 1))) //???????��???????????��?????????????????��??
      {
        LCD_DrawPixel(LayerIndex, (Xpos + j), Ypos, DrawProp[LayerIndex].TextColor);
      }
      else //????????????????????????????????
      {
        LCD_DrawPixel(LayerIndex, (Xpos + j), Ypos, DrawProp[LayerIndex].BackColor);
      }
    }
    Ypos++;
  }
}

/**
 * @brief ????????????
 * @param Xpos??X??????
 * @param Ypos??Y??????
 * @param RGB_Code??????????
 * @param LayerIndex???????????
 * @retval ??
 */
void LCD_DrawPixel(uint16_t LayerIndex, uint16_t Xpos, uint16_t Ypos, uint32_t RGB_Code)
{

  if (hltdc.LayerCfg[LayerIndex].PixelFormat == LTDC_PIXEL_FORMAT_ARGB8888)
  {
    *(__IO uint32_t *)((hltdc.LayerCfg[LayerIndex].FBStartAdress) + (4 * (Ypos * LCD_GetXSize(LayerIndex) + Xpos))) =
        RGB_Code;
  }
  else if (hltdc.LayerCfg[LayerIndex].PixelFormat == LTDC_PIXEL_FORMAT_RGB888)
  {
    *(__IO uint8_t *)(hltdc.LayerCfg[LayerIndex].FBStartAdress + (3 * (Ypos * LCD_GetXSize(LayerIndex) + Xpos)) + 2) =
        0xFF & (RGB_Code >> 16);
    *(__IO uint8_t *)(hltdc.LayerCfg[LayerIndex].FBStartAdress + (3 * (Ypos * LCD_GetXSize(LayerIndex) + Xpos)) + 1) =
        0xFF & (RGB_Code >> 8);
    *(__IO uint8_t *)(hltdc.LayerCfg[LayerIndex].FBStartAdress + (3 * (Ypos * LCD_GetXSize(LayerIndex) + Xpos))) =
        0xFF & RGB_Code;
  }
  else if ((hltdc.LayerCfg[LayerIndex].PixelFormat == LTDC_PIXEL_FORMAT_RGB565) ||
           (hltdc.LayerCfg[LayerIndex].PixelFormat == LTDC_PIXEL_FORMAT_ARGB4444) ||
           (hltdc.LayerCfg[LayerIndex].PixelFormat == LTDC_PIXEL_FORMAT_AL88))
  {
    *(__IO uint16_t *)(hltdc.LayerCfg[LayerIndex].FBStartAdress + (2 * (Ypos * LCD_GetXSize(LayerIndex) + Xpos))) =
        (uint16_t)RGB_Code;
  }
  else
  {
    *(__IO uint16_t *)(hltdc.LayerCfg[LayerIndex].FBStartAdress + (2 * (Ypos * LCD_GetXSize(LayerIndex) + Xpos))) =
        (uint16_t)RGB_Code;
  }
}

/**
 * @brief  ??????
 * @retval ??
 */
void LCD_DisplayOn(void)
{
  /* ????? */
  __HAL_LTDC_ENABLE(&hltdc);
  HAL_GPIO_WritePin(LTDC_BL_GPIO_Port, LTDC_BL_Pin, GPIO_PIN_SET); /* ??????*/
}

/**
 * @brief  ???????
 * @retval ??
 */
void LCD_DisplayOff(void)
{
  /* ????? */
  __HAL_LTDC_DISABLE(&hltdc);
  HAL_GPIO_WritePin(LTDC_BL_GPIO_Port, LTDC_BL_Pin, GPIO_PIN_RESET); /*?????*/
}

/**
 * @brief  LCD?????????
 * @param  Color: ???????
 * @retval None
 */
void LCD_Clear(uint16_t LayerIndex, uint32_t Color)
{
  /* ???? */
  LL_FillBuffer(LayerIndex, (uint32_t *)(hltdc.LayerCfg[LayerIndex].FBStartAdress), LCD_GetXSize(LayerIndex),
                LCD_GetYSize(LayerIndex), 0, Color);
}

/**
 * @brief  ????????????
 * @param  LayerIndex: ?????
 * @param  pDst: ?????????????
 * @param  xSize: ?????????
 * @param  ySize: ?????????
 * @param  OffLine: ?????
 * @param  ColorIndex: ??????
 * @retval None
 */
static void LL_FillBuffer(uint32_t LayerIndex, void *pDst, uint32_t xSize, uint32_t ySize, uint32_t OffLine,
                          uint32_t ColorIndex)
{
  hdma2d.Init.Mode = DMA2D_R2M;
  if (hltdc.LayerCfg[LayerIndex].PixelFormat == LTDC_PIXEL_FORMAT_RGB565)
  {
    hdma2d.Init.ColorMode = DMA2D_OUTPUT_RGB565;
  }
  else if (hltdc.LayerCfg[LayerIndex].PixelFormat == LTDC_PIXEL_FORMAT_ARGB8888)
  {
    hdma2d.Init.ColorMode = DMA2D_OUTPUT_ARGB8888;
  }
  else if (hltdc.LayerCfg[LayerIndex].PixelFormat == LTDC_PIXEL_FORMAT_RGB888)
  {
    hdma2d.Init.ColorMode = DMA2D_OUTPUT_RGB888;
  }
  else if (hltdc.LayerCfg[LayerIndex].PixelFormat == LTDC_PIXEL_FORMAT_ARGB1555)
  {
    hdma2d.Init.ColorMode = DMA2D_OUTPUT_ARGB1555;
  }
  else if (hltdc.LayerCfg[LayerIndex].PixelFormat == LTDC_PIXEL_FORMAT_ARGB4444)
  {
    hdma2d.Init.ColorMode = DMA2D_OUTPUT_ARGB4444;
  }
  hdma2d.Init.OutputOffset = OffLine;

  hdma2d.Instance = DMA2D;

  /* DMA2D ????? */
  if (HAL_DMA2D_Init(&hdma2d) == HAL_OK)
  {
    if (HAL_DMA2D_ConfigLayer(&hdma2d, LayerIndex) == HAL_OK)
    {
      if (HAL_DMA2D_Start(&hdma2d, ColorIndex, (uint32_t)pDst, xSize, ySize) == HAL_OK)
      {
        /* DMA??????? */
        HAL_DMA2D_PollForTransfer(&hdma2d, 10);
      }
    }
  }
}
/* USER CODE END 4 */

void Error_Handler(void)
{
}

/************************ (C) COPYRIGHT STMicroelectronics *****END OF FILE****/
